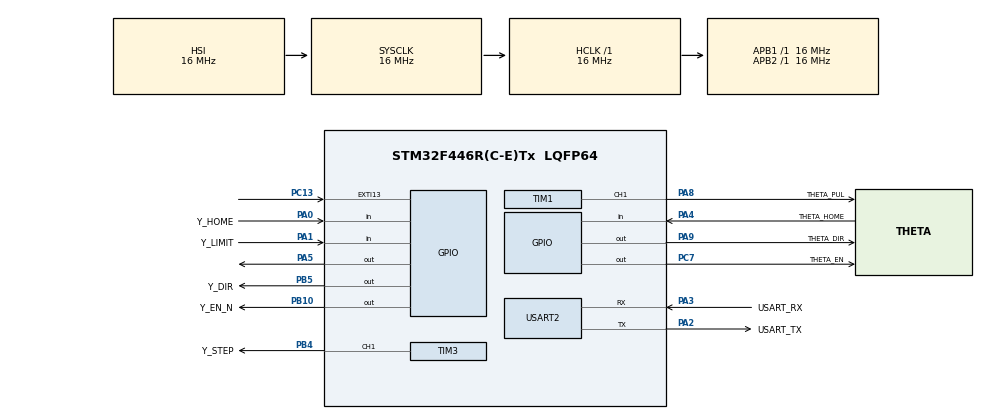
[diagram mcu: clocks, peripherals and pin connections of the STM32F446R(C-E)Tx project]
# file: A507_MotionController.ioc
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Mcu.Family=STM32F4
Mcu.Name=STM32F446R(C-E)Tx
Mcu.Package=LQFP64
NUCLEO-F446RE.BUTTON=1
NUCLEO-F446RE.LD1=true
NVIC.EXTI15_10_IRQn=true\:0\:0\:false\:false\:true\:false\:true\:true
NVIC.PriorityGroup=NVIC_PRIORITYGROUP_0
NVIC.USART2_IRQn=true\:0\:0\:false\:false\:true\:true\:true\:true
PA0-WKUP.GPIO_Label=Y_HOME
PA0-WKUP.GPIO_PuPd=GPIO_PULLUP
PA0-WKUP.Signal=GPIO_Input
PA1.GPIO_Label=Y_LIMIT
PA1.GPIO_PuPd=GPIO_PULLUP
PA1.Signal=GPIO_Input
PA13.GPIO_Label=TMS
PA13.Mode=Serial_Wire
PA13.Signal=SYS_JTMS-SWDIO
PA14.GPIO_Label=TCK
PA14.Mode=Serial_Wire
PA14.Signal=SYS_JTCK-SWCLK
PA2.GPIO_Label=USART_TX
PA2.Mode=Asynchronous
PA2.Signal=USART2_TX
PA3.GPIO_Label=USART_RX
PA3.Mode=Asynchronous
PA3.Signal=USART2_RX
PA4.GPIO_Label=THETA_HOME
PA4.GPIO_PuPd=GPIO_PULLUP
PA4.Signal=GPIO_Input
PA5.Signal=GPIO_Output
PA8.GPIO_Label=THETA_PUL
PA8.Signal=S_TIM1_CH1
PA9.GPIO_Label=THETA_DIR
PA9.Signal=GPIO_Output
PB10.GPIO_Label=Y_EN_N
PB10.PinState=GPIO_PIN_SET
PB10.Signal=GPIO_Output
PB3.GPIO_Label=SWO
PB3.Signal=SYS_JTDO-SWO
PB4.GPIO_Label=Y_STEP
PB4.Signal=S_TIM3_CH1
PB5.GPIO_Label=Y_DIR
PB5.Signal=GPIO_Output
PC13.Signal=GPXTI13
PC14-OSC32_IN.Signal=RCC_OSC32_IN
PC15-OSC32_OUT.Signal=RCC_OSC32_OUT
PC7.GPIO_Label=THETA_EN
PC7.Signal=GPIO_Output
PH0-OSC_IN.Signal=RCC_OSC_IN
PH1-OSC_OUT.Signal=RCC_OSC_OUT
ProjectManager.HeapSize=0x200
ProjectManager.StackSize=0x400
ProjectManager.TargetToolchain=CMake
RCC.AHBFreq_Value=16000000
RCC.APB1Freq_Value=16000000
RCC.APB1TimFreq_Value=16000000
RCC.APB2Freq_Value=16000000
RCC.APB2TimFreq_Value=16000000
RCC.CortexFreq_Value=16000000
RCC.FLatency-AdvancedSettings=FLASH_LATENCY_0
RCC.HCLKFreq_Value=16000000
RCC.HSE_VALUE=8000000
RCC.HSI_VALUE=16000000
RCC.LSE_VALUE=32768
RCC.PLLN=336
RCC.PLLP=RCC_PLLP_DIV4
RCC.SYSCLKFreq_VALUE=16000000
RCC.USBFreq_Value=168000000
RCC.VCOOutputFreq_Value=336000000
SH.S_TIM1_CH1.0=TIM1_CH1,PWM Generation1 CH1
SH.S_TIM3_CH1.0=TIM3_CH1,PWM Generation1 CH1
TIM1.AutoReloadPreload=TIM_AUTORELOAD_PRELOAD_ENABLE
TIM1.Channel-PWM\ Generation1\ CH1=TIM_CHANNEL_1
TIM1.OC1Preload_PWM=DISABLE
TIM1.Period=999
TIM1.Prescaler=15
TIM1.Pulse-PWM\ Generation1\ CH1=500
TIM3.AutoReloadPreload=TIM_AUTORELOAD_PRELOAD_ENABLE
TIM3.Channel-PWM\ Generation1\ CH1=TIM_CHANNEL_1
TIM3.OC1Preload_PWM=DISABLE
TIM3.Period=999
TIM3.Prescaler=15
TIM3.Pulse-PWM\ Generation1\ CH1=500
USART2.VirtualMode=VM_ASYNC
VP_NUCLEO-F446RE_VS_BSP_COMMON.Mode=COMMON
VP_TIM1_VS_ClockSourceINT.Mode=Internal
VP_TIM3_VS_ClockSourceINT.Mode=Internal
board=NUCLEO-F446RE

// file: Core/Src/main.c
/* USER CODE BEGIN Header */
/**
  ******************************************************************************
  * @file           : main.c
  * @brief          : Main program body
  ******************************************************************************
  * @attention
  *
  * Copyright (c) 2026 STMicroelectronics.
  * All rights reserved.
  *
  * This software is licensed under terms that can be found in the LICENSE file
  * in the root directory of this software component.
  * If no LICENSE file comes with this software, it is provided AS-IS.
  *
  ******************************************************************************
  */
/* USER CODE END Header */
#include "main.h"

/* USER CODE BEGIN Includes */
#include "app.h"
/* USER CODE END Includes */

TIM_HandleTypeDef htim1;
TIM_HandleTypeDef htim3;

UART_HandleTypeDef huart2;

void SystemClock_Config(void);
static void MX_GPIO_Init(void);
static void MX_TIM1_Init(void);
static void MX_TIM3_Init(void);
static void MX_USART2_UART_Init(void);

int main(void)
{

  /* MCU Configuration--------------------------------------------------------*/

  /* Reset of all peripherals, Initializes the Flash interface and the Systick. */
  HAL_Init();

  /* Configure the system clock */
  SystemClock_Config();

  /* Initialize all configured peripherals */
  MX_GPIO_Init();
  MX_TIM1_Init();
  MX_TIM3_Init();
  MX_USART2_UART_Init();
  /* USER CODE BEGIN 2 */
  App_Init(&huart2);
  /* USER CODE END 2 */

  /* Initialize leds */
  BSP_LED_Init(LED2);

  /* Initialize USER push-button, will be used to trigger an interrupt each time it's pressed.*/
  BSP_PB_Init(BUTTON_USER, BUTTON_MODE_EXTI);

  /* Infinite loop */
  while (1)
  {

    /* USER CODE BEGIN 3 */
    App_Poll();
  }
  /* USER CODE END 3 */
}

void SystemClock_Config(void)
{
  RCC_OscInitTypeDef RCC_OscInitStruct = {0};
  RCC_ClkInitTypeDef RCC_ClkInitStruct = {0};

  /** Configure the main internal regulator output voltage
  */
  __HAL_RCC_PWR_CLK_ENABLE();
  __HAL_PWR_VOLTAGESCALING_CONFIG(PWR_REGULATOR_VOLTAGE_SCALE3);

  /** Initializes the RCC Oscillators according to the specified parameters
  * in the RCC_OscInitTypeDef structure.
  */
  RCC_OscInitStruct.OscillatorType = RCC_OSCILLATORTYPE_HSI;
  RCC_OscInitStruct.HSIState = RCC_HSI_ON;
  RCC_OscInitStruct.HSICalibrationValue = RCC_HSICALIBRATION_DEFAULT;
  RCC_OscInitStruct.PLL.PLLState = RCC_PLL_NONE;
  if (HAL_RCC_OscConfig(&RCC_OscInitStruct) != HAL_OK)
  {
    Error_Handler();
  }

  /** Initializes the CPU, AHB and APB buses clocks
  */
  RCC_ClkInitStruct.ClockType = RCC_CLOCKTYPE_HCLK|RCC_CLOCKTYPE_SYSCLK
                              |RCC_CLOCKTYPE_PCLK1|RCC_CLOCKTYPE_PCLK2;
  RCC_ClkInitStruct.SYSCLKSource = RCC_SYSCLKSOURCE_HSI;
  RCC_ClkInitStruct.AHBCLKDivider = RCC_SYSCLK_DIV1;
  RCC_ClkInitStruct.APB1CLKDivider = RCC_HCLK_DIV1;
  RCC_ClkInitStruct.APB2CLKDivider = RCC_HCLK_DIV1;

  if (HAL_RCC_ClockConfig(&RCC_ClkInitStruct, FLASH_LATENCY_0) != HAL_OK)
  {
    Error_Handler();
  }
}

static void MX_TIM1_Init(void)
{

  TIM_ClockConfigTypeDef sClockSourceConfig = {0};
  TIM_MasterConfigTypeDef sMasterConfig = {0};
  TIM_OC_InitTypeDef sConfigOC = {0};
  TIM_BreakDeadTimeConfigTypeDef sBreakDeadTimeConfig = {0};

  htim1.Instance = TIM1;
  htim1.Init.Prescaler = 15;
  htim1.Init.CounterMode = TIM_COUNTERMODE_UP;
  htim1.Init.Period = 999;
  htim1.Init.ClockDivision = TIM_CLOCKDIVISION_DIV1;
  htim1.Init.RepetitionCounter = 0;
  htim1.Init.AutoReloadPreload = TIM_AUTORELOAD_PRELOAD_ENABLE;
  if (HAL_TIM_Base_Init(&htim1) != HAL_OK)
  {
    Error_Handler();
  }
  sClockSourceConfig.ClockSource = TIM_CLOCKSOURCE_INTERNAL;
  if (HAL_TIM_ConfigClockSource(&htim1, &sClockSourceConfig) != HAL_OK)
  {
    Error_Handler();
  }
  if (HAL_TIM_PWM_Init(&htim1) != HAL_OK)
  {
    Error_Handler();
  }
  sMasterConfig.MasterOutputTrigger = TIM_TRGO_RESET;
  sMasterConfig.MasterSlaveMode = TIM_MASTERSLAVEMODE_DISABLE;
  if (HAL_TIMEx_MasterConfigSynchronization(&htim1, &sMasterConfig) != HAL_OK)
  {
    Error_Handler();
  }
  sConfigOC.OCMode = TIM_OCMODE_PWM1;
  sConfigOC.Pulse = 500;
  sConfigOC.OCPolarity = TIM_OCPOLARITY_HIGH;
  sConfigOC.OCNPolarity = TIM_OCNPOLARITY_HIGH;
  sConfigOC.OCFastMode = TIM_OCFAST_DISABLE;
  sConfigOC.OCIdleState = TIM_OCIDLESTATE_RESET;
  sConfigOC.OCNIdleState = TIM_OCNIDLESTATE_RESET;
  if (HAL_TIM_PWM_ConfigChannel(&htim1, &sConfigOC, TIM_CHANNEL_1) != HAL_OK)
  {
    Error_Handler();
  }
  __HAL_TIM_DISABLE_OCxPRELOAD(&htim1, TIM_CHANNEL_1);
  sBreakDeadTimeConfig.OffStateRunMode = TIM_OSSR_DISABLE;
  sBreakDeadTimeConfig.OffStateIDLEMode = TIM_OSSI_DISABLE;
  sBreakDeadTimeConfig.LockLevel = TIM_LOCKLEVEL_OFF;
  sBreakDeadTimeConfig.DeadTime = 0;
  sBreakDeadTimeConfig.BreakState = TIM_BREAK_DISABLE;
  sBreakDeadTimeConfig.BreakPolarity = TIM_BREAKPOLARITY_HIGH;
  sBreakDeadTimeConfig.AutomaticOutput = TIM_AUTOMATICOUTPUT_DISABLE;
  if (HAL_TIMEx_ConfigBreakDeadTime(&htim1, &sBreakDeadTimeConfig) != HAL_OK)
  {
    Error_Handler();
  }
  HAL_TIM_MspPostInit(&htim1);

}

static void MX_TIM3_Init(void)
{

  TIM_ClockConfigTypeDef sClockSourceConfig = {0};
  TIM_MasterConfigTypeDef sMasterConfig = {0};
  TIM_OC_InitTypeDef sConfigOC = {0};

  htim3.Instance = TIM3;
  htim3.Init.Prescaler = 15;
  htim3.Init.CounterMode = TIM_COUNTERMODE_UP;
  htim3.Init.Period = 999;
  htim3.Init.ClockDivision = TIM_CLOCKDIVISION_DIV1;
  htim3.Init.AutoReloadPreload = TIM_AUTORELOAD_PRELOAD_ENABLE;
  if (HAL_TIM_Base_Init(&htim3) != HAL_OK)
  {
    Error_Handler();
  }
  sClockSourceConfig.ClockSource = TIM_CLOCKSOURCE_INTERNAL;
  if (HAL_TIM_ConfigClockSource(&htim3, &sClockSourceConfig) != HAL_OK)
  {
    Error_Handler();
  }
  if (HAL_TIM_PWM_Init(&htim3) != HAL_OK)
  {
    Error_Handler();
  }
  sMasterConfig.MasterOutputTrigger = TIM_TRGO_RESET;
  sMasterConfig.MasterSlaveMode = TIM_MASTERSLAVEMODE_DISABLE;
  if (HAL_TIMEx_MasterConfigSynchronization(&htim3, &sMasterConfig) != HAL_OK)
  {
    Error_Handler();
  }
  sConfigOC.OCMode = TIM_OCMODE_PWM1;
  sConfigOC.Pulse = 500;
  sConfigOC.OCPolarity = TIM_OCPOLARITY_HIGH;
  sConfigOC.OCFastMode = TIM_OCFAST_DISABLE;
  if (HAL_TIM_PWM_ConfigChannel(&htim3, &sConfigOC, TIM_CHANNEL_1) != HAL_OK)
  {
    Error_Handler();
  }
  __HAL_TIM_DISABLE_OCxPRELOAD(&htim3, TIM_CHANNEL_1);
  HAL_TIM_MspPostInit(&htim3);

}

static void MX_USART2_UART_Init(void)
{

  huart2.Instance = USART2;
  huart2.Init.BaudRate = 115200;
  huart2.Init.WordLength = UART_WORDLENGTH_8B;
  huart2.Init.StopBits = UART_STOPBITS_1;
  huart2.Init.Parity = UART_PARITY_NONE;
  huart2.Init.Mode = UART_MODE_TX_RX;
  huart2.Init.HwFlowCtl = UART_HWCONTROL_NONE;
  huart2.Init.OverSampling = UART_OVERSAMPLING_16;
  if (HAL_UART_Init(&huart2) != HAL_OK)
  {
    Error_Handler();
  }

}

static void MX_GPIO_Init(void)
{
  GPIO_InitTypeDef GPIO_InitStruct = {0};

  /* GPIO Ports Clock Enable */
  __HAL_RCC_GPIOC_CLK_ENABLE();
  __HAL_RCC_GPIOH_CLK_ENABLE();
  __HAL_RCC_GPIOA_CLK_ENABLE();
  __HAL_RCC_GPIOB_CLK_ENABLE();

  /*Configure GPIO pin Output Level */
  HAL_GPIO_WritePin(Y_EN_N_GPIO_Port, Y_EN_N_Pin, GPIO_PIN_SET);

  /*Configure GPIO pin Output Level */
  HAL_GPIO_WritePin(THETA_EN_GPIO_Port, THETA_EN_Pin, GPIO_PIN_RESET);

  /*Configure GPIO pin Output Level */
  HAL_GPIO_WritePin(THETA_DIR_GPIO_Port, THETA_DIR_Pin, GPIO_PIN_RESET);

  /*Configure GPIO pin Output Level */
  HAL_GPIO_WritePin(Y_DIR_GPIO_Port, Y_DIR_Pin, GPIO_PIN_RESET);

  /*Configure GPIO pins : Y_HOME_Pin Y_LIMIT_Pin THETA_HOME_Pin */
  GPIO_InitStruct.Pin = Y_HOME_Pin|Y_LIMIT_Pin|THETA_HOME_Pin;
  GPIO_InitStruct.Mode = GPIO_MODE_INPUT;
  GPIO_InitStruct.Pull = GPIO_PULLUP;
  HAL_GPIO_Init(GPIOA, &GPIO_InitStruct);

  /*Configure GPIO pins : Y_EN_N_Pin Y_DIR_Pin */
  GPIO_InitStruct.Pin = Y_EN_N_Pin|Y_DIR_Pin;
  GPIO_InitStruct.Mode = GPIO_MODE_OUTPUT_PP;
  GPIO_InitStruct.Pull = GPIO_NOPULL;
  GPIO_InitStruct.Speed = GPIO_SPEED_FREQ_LOW;
  HAL_GPIO_Init(GPIOB, &GPIO_InitStruct);

  /*Configure GPIO pin : THETA_EN_Pin */
  GPIO_InitStruct.Pin = THETA_EN_Pin;
  GPIO_InitStruct.Mode = GPIO_MODE_OUTPUT_PP;
  GPIO_InitStruct.Pull = GPIO_NOPULL;
  GPIO_InitStruct.Speed = GPIO_SPEED_FREQ_LOW;
  HAL_GPIO_Init(THETA_EN_GPIO_Port, &GPIO_InitStruct);

  /*Configure GPIO pin : THETA_DIR_Pin */
  GPIO_InitStruct.Pin = THETA_DIR_Pin;
  GPIO_InitStruct.Mode = GPIO_MODE_OUTPUT_PP;
  GPIO_InitStruct.Pull = GPIO_NOPULL;
  GPIO_InitStruct.Speed = GPIO_SPEED_FREQ_LOW;
  HAL_GPIO_Init(THETA_DIR_GPIO_Port, &GPIO_InitStruct);

}

/* USER CODE BEGIN 4 */
void HAL_UART_RxCpltCallback(UART_HandleTypeDef *huart)
{
  App_UartRxComplete(huart);
}

void HAL_UART_ErrorCallback(UART_HandleTypeDef *huart)
{
  App_UartError(huart);
}
/* USER CODE END 4 */

void Error_Handler(void)
{
  __disable_irq();
  while (1)
  {
  }
}
